BO_ 432 STANDSTILL: 7 VSA
 SG_ WHEELS_MOVING : 12|1@0+ (1,0) [0|1] "" EON

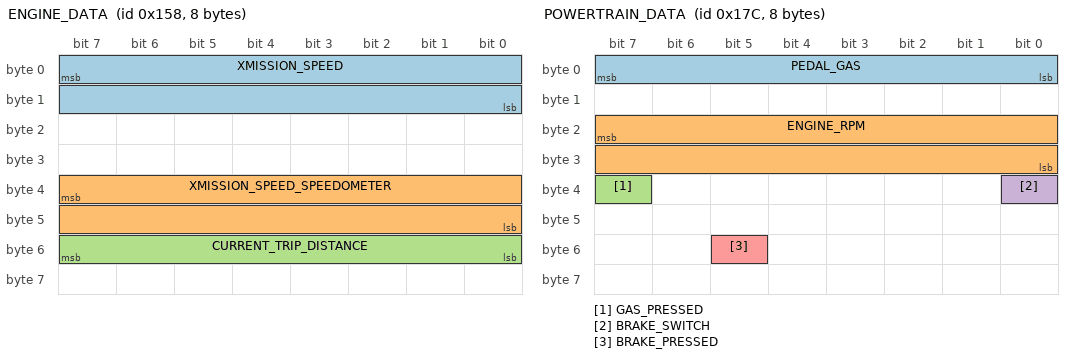
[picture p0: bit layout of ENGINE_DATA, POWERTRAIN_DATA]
BO_ 344 ENGINE_DATA: 8 PCM
 SG_ XMISSION_SPEED : 7|16@0+ (0.01,0) [0|250] "kph" EON
 SG_ XMISSION_SPEED_SPEEDOMETER : 39|16@0+ (0.01,0) [0|250] "kph" EON
 SG_ CURRENT_TRIP_DISTANCE : 55|8@0+ (10,0) [0|2550] "m" XXX

BO_ 380 POWERTRAIN_DATA: 8 PCM
 SG_ PEDAL_GAS : 7|8@0+ (1,0) [0|255] "" EON
 SG_ ENGINE_RPM : 23|16@0+ (1,0) [0|15000] "rpm" EON
 SG_ GAS_PRESSED : 39|1@0+ (1,0) [0|1] "" EON
 SG_ BRAKE_SWITCH : 32|1@0+ (1,0) [0|1] "" EON
 SG_ BRAKE_PRESSED : 53|1@0+ (1,0) [0|1] "" EON

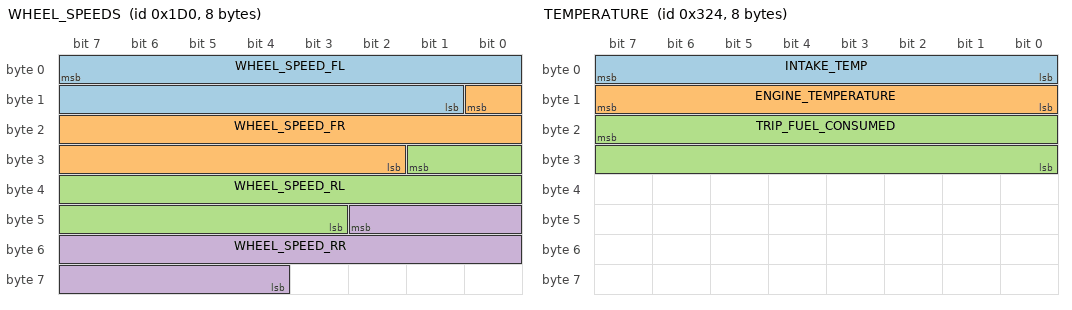
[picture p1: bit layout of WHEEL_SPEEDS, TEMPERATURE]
BO_ 464 WHEEL_SPEEDS: 8 VSA
 SG_ WHEEL_SPEED_FL : 7|15@0+ (0.01,0) [0|250] "kph" EON
 SG_ WHEEL_SPEED_FR : 8|15@0+ (0.01,0) [0|250] "kph" EON
 SG_ WHEEL_SPEED_RL : 25|15@0+ (0.01,0) [0|250] "kph" EON
 SG_ WHEEL_SPEED_RR : 42|15@0+ (0.01,0) [0|250] "kph" EON

BO_ 490 VEHICLE_DYNAMICS: 8 VSA
 SG_ LAT_ACCEL : 7|16@0- (0.0015,0) [-20|20] "m/s2" EON
 SG_ LONG_ACCEL : 23|16@0- (0.0015,0) [-20|20] "m/s2" EON

BO_ 777 CAR_SPEED: 8 PCM
 SG_ ROUGH_CAR_SPEED : 39|16@0+ (0.01,0) [0|65535] "kph" XXX

VAL_ 401 GEAR_SHIFTER 32 "L" 16 "S" 8 "D" 4 "N" 2 "R" 1 "P";
BO_ 401 GEARBOX: 8 PCM
 SG_ GEAR_SHIFTER : 5|6@0+ (1,0) [0|63] "" EON

VAL_ 545 ECON_MODE 3 "on" 0 "off" ;
BO_ 545 ECON_STATUS: 6 XXX
 SG_ ECON_MODE : 37|2@0+ (1,0) [0|3] "" EON

BO_ 804 TEMPERATURE: 8 PCM
 SG_ INTAKE_TEMP        : 7|8@0+ (1,-40) [-40|215] "degC" EON
 SG_ ENGINE_TEMPERATURE : 15|8@0+ (1,-40) [-40|215] "degC" EON
 SG_ TRIP_FUEL_CONSUMED : 23|16@0+ (0.001,0) [0|65.535] "" EON
